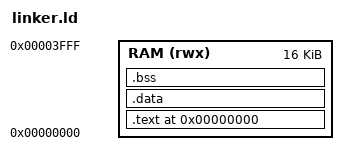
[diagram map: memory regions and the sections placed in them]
ENTRY(_start)

MEMORY
{
    RAM (rwx) : ORIGIN = 0x00000000, LENGTH = 16K
}

SECTIONS
{
    . = ORIGIN(RAM);

    .text : {
        *(.text.start)
        *(.text*)
        *(.rodata*)
        *(.srodata*)
    } > RAM

    .data : {
        *(.data*)
        *(.sdata*)
    } > RAM

    .bss (NOLOAD) : {
        *(.bss*)
        *(.sbss*)
        *(COMMON)
    } > RAM

    . = ALIGN(4);
    PROVIDE(__stack_top = ORIGIN(RAM) + LENGTH(RAM) - 4);
}

